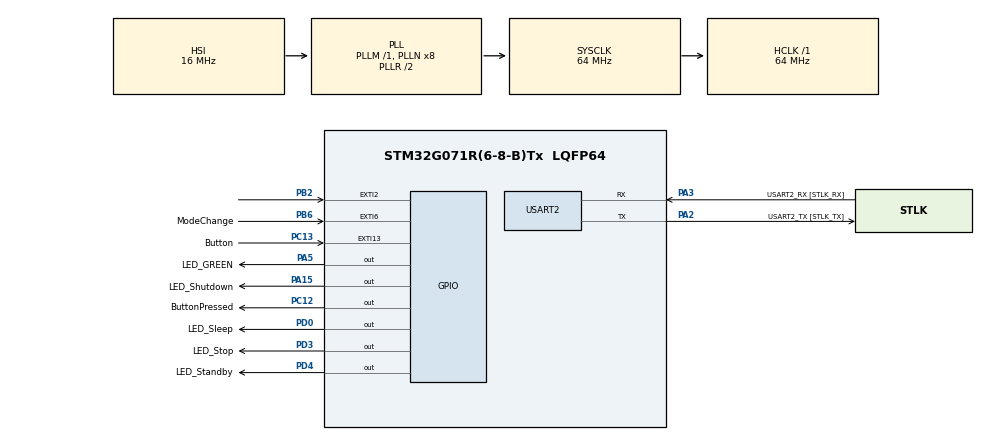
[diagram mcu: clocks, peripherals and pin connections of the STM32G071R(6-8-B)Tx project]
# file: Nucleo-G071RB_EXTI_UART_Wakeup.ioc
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Dma.Request0=USART2_RX
Dma.Request1=USART2_TX
Dma.USART2_RX.0.Direction=DMA_PERIPH_TO_MEMORY
Dma.USART2_RX.0.EventEnable=DISABLE
Dma.USART2_RX.0.Instance=DMA1_Channel1
Dma.USART2_RX.0.MemDataAlignment=DMA_MDATAALIGN_BYTE
Dma.USART2_RX.0.MemInc=DMA_MINC_ENABLE
Dma.USART2_RX.0.Mode=DMA_CIRCULAR
Dma.USART2_RX.0.PeriphDataAlignment=DMA_PDATAALIGN_BYTE
Dma.USART2_RX.0.PeriphInc=DMA_PINC_DISABLE
Dma.USART2_RX.0.Polarity=HAL_DMAMUX_REQ_GEN_RISING
Dma.USART2_RX.0.Priority=DMA_PRIORITY_LOW
Dma.USART2_RX.0.RequestNumber=1
Dma.USART2_RX.0.SignalID=NONE
Dma.USART2_RX.0.SyncEnable=DISABLE
Dma.USART2_RX.0.SyncPolarity=HAL_DMAMUX_SYNC_NO_EVENT
Dma.USART2_RX.0.SyncRequestNumber=1
Dma.USART2_RX.0.SyncSignalID=NONE
Dma.USART2_TX.1.Direction=DMA_MEMORY_TO_PERIPH
Dma.USART2_TX.1.EventEnable=DISABLE
Dma.USART2_TX.1.Instance=DMA1_Channel2
Dma.USART2_TX.1.MemDataAlignment=DMA_MDATAALIGN_BYTE
Dma.USART2_TX.1.MemInc=DMA_MINC_ENABLE
Dma.USART2_TX.1.Mode=DMA_NORMAL
Dma.USART2_TX.1.PeriphDataAlignment=DMA_PDATAALIGN_BYTE
Dma.USART2_TX.1.PeriphInc=DMA_PINC_DISABLE
Dma.USART2_TX.1.Polarity=HAL_DMAMUX_REQ_GEN_RISING
Dma.USART2_TX.1.Priority=DMA_PRIORITY_LOW
Dma.USART2_TX.1.RequestNumber=1
Dma.USART2_TX.1.SignalID=NONE
Dma.USART2_TX.1.SyncEnable=DISABLE
Dma.USART2_TX.1.SyncPolarity=HAL_DMAMUX_SYNC_NO_EVENT
Dma.USART2_TX.1.SyncRequestNumber=1
Dma.USART2_TX.1.SyncSignalID=NONE
Mcu.Family=STM32G0
Mcu.Name=STM32G071R(6-8-B)Tx
Mcu.Package=LQFP64
NVIC.DMA1_Channel1_IRQn=true\:0\:0\:false\:false\:true\:false\:true\:true
NVIC.DMA1_Channel2_3_IRQn=true\:0\:0\:false\:false\:true\:false\:true\:true
NVIC.EXTI2_3_IRQn=true\:0\:0\:false\:false\:true\:true\:true\:true
NVIC.EXTI4_15_IRQn=true\:0\:0\:false\:false\:true\:true\:true\:true
NVIC.USART2_IRQn=true\:0\:0\:false\:false\:true\:true\:true\:true
PA13.GPIO_Label=TMS
PA13.Mode=Serial_Wire
PA13.Signal=SYS_SWDIO
PA14-BOOT0.GPIO_Label=TCK
PA14-BOOT0.Mode=Serial_Wire
PA14-BOOT0.Signal=SYS_SWCLK
PA15.GPIO_Label=LED_Shutdown
PA15.Signal=GPIO_Output
PA2.GPIO_Label=USART2_TX [STLK_TX]
PA2.Mode=Asynchronous
PA2.Signal=USART2_TX
PA3.GPIO_Label=USART2_RX [STLK_RX]
PA3.GPIO_PuPd=GPIO_NOPULL
PA3.Mode=Asynchronous
PA3.Signal=USART2_RX
PA5.GPIO_Label=LED_GREEN
PA5.GPIO_Speed=GPIO_SPEED_FREQ_HIGH
PA5.Signal=GPIO_Output
PB2.GPIO_ModeDefaultEXTI=GPIO_MODE_IT_RISING_FALLING
PB2.GPIO_PuPd=GPIO_PULLUP
PB2.Signal=GPXTI2
PB6.GPIO_Label=ModeChange
PB6.GPIO_ModeDefaultEXTI=GPIO_MODE_IT_RISING_FALLING
PB6.GPIO_PuPd=GPIO_PULLUP
PB6.Signal=GPXTI6
PC12.GPIO_Label=ButtonPressed
PC12.Signal=GPIO_Output
PC13.GPIO_Label=Button
PC13.GPIO_ModeDefaultEXTI=GPIO_MODE_IT_RISING_FALLING
PC13.GPIO_PuPd=GPIO_NOPULL
PC13.Signal=GPXTI13
PD0.GPIO_Label=LED_Sleep
PD0.Signal=GPIO_Output
PD3.GPIO_Label=LED_Stop
PD3.Signal=GPIO_Output
PD4.GPIO_Label=LED_Standby
PD4.Signal=GPIO_Output
ProjectManager.HeapSize=0x200
ProjectManager.StackSize=0x400
ProjectManager.TargetToolchain=STM32CubeIDE
RCC.ADCFreq_Value=64000000
RCC.AHBFreq_Value=64000000
RCC.CortexFreq_Value=64000000
RCC.EXTERNAL_CLOCK_VALUE=12288000
RCC.HCLKFreq_Value=64000000
RCC.HSE_VALUE=8000000
RCC.HSI_VALUE=16000000
RCC.LSE_VALUE=32768
RCC.RCC_MCO1Source=RCC_MCO1SOURCE_HSI
RCC.SYSCLKFreq_VALUE=64000000
RCC.SYSCLKSource=RCC_SYSCLKSOURCE_PLLCLK
RCC.USART2CLockSelection=RCC_USART2CLKSOURCE_HSI
RCC.VCOOutputFreq_Value=128000000
USART2.VirtualMode-Asynchronous=VM_ASYNC
board=NUCLEO-G071RB

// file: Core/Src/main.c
/* USER CODE BEGIN Header */
/**
  ******************************************************************************
  * @file           : main.c
  * @brief          : Main program body
  ******************************************************************************
  * @attention
  *
  * Copyright (c) 2025 STMicroelectronics.
  * All rights reserved.
  *
  * This software is licensed under terms that can be found in the LICENSE file
  * in the root directory of this software component.
  * If no LICENSE file comes with this software, it is provided AS-IS.
  *
  ******************************************************************************
  */
/* USER CODE END Header */
#include "main.h"

UART_HandleTypeDef huart2;
DMA_HandleTypeDef hdma_usart2_rx;
DMA_HandleTypeDef hdma_usart2_tx;

void SystemClock_Config(void);
static void MX_GPIO_Init(void);
static void MX_DMA_Init(void);
static void MX_USART2_UART_Init(void);

int main(void)
{

  /* MCU Configuration--------------------------------------------------------*/

  /* Reset of all peripherals, Initializes the Flash interface and the Systick. */
  HAL_Init();

  /* Configure the system clock */
  SystemClock_Config();

  /* Initialize all configured peripherals */
  MX_GPIO_Init();
  MX_DMA_Init();
  MX_USART2_UART_Init();

  /* Infinite loop */
  /* USER CODE BEGIN WHILE */
  PollingInit();
  while (1)
  {
	  PollingRoutine();
    /* USER CODE END WHILE */

  }
}

void SystemClock_Config(void)
{
  RCC_OscInitTypeDef RCC_OscInitStruct = {0};
  RCC_ClkInitTypeDef RCC_ClkInitStruct = {0};

  /** Configure the main internal regulator output voltage
  */
  HAL_PWREx_ControlVoltageScaling(PWR_REGULATOR_VOLTAGE_SCALE1);

  /** Initializes the RCC Oscillators according to the specified parameters
  * in the RCC_OscInitTypeDef structure.
  */
  RCC_OscInitStruct.OscillatorType = RCC_OSCILLATORTYPE_HSI;
  RCC_OscInitStruct.HSIState = RCC_HSI_ON;
  RCC_OscInitStruct.HSIDiv = RCC_HSI_DIV1;
  RCC_OscInitStruct.HSICalibrationValue = RCC_HSICALIBRATION_DEFAULT;
  RCC_OscInitStruct.PLL.PLLState = RCC_PLL_ON;
  RCC_OscInitStruct.PLL.PLLSource = RCC_PLLSOURCE_HSI;
  RCC_OscInitStruct.PLL.PLLM = RCC_PLLM_DIV1;
  RCC_OscInitStruct.PLL.PLLN = 8;
  RCC_OscInitStruct.PLL.PLLP = RCC_PLLP_DIV2;
  RCC_OscInitStruct.PLL.PLLQ = RCC_PLLQ_DIV2;
  RCC_OscInitStruct.PLL.PLLR = RCC_PLLR_DIV2;
  if (HAL_RCC_OscConfig(&RCC_OscInitStruct) != HAL_OK)
  {
    Error_Handler();
  }

  /** Initializes the CPU, AHB and APB buses clocks
  */
  RCC_ClkInitStruct.ClockType = RCC_CLOCKTYPE_HCLK|RCC_CLOCKTYPE_SYSCLK
                              |RCC_CLOCKTYPE_PCLK1;
  RCC_ClkInitStruct.SYSCLKSource = RCC_SYSCLKSOURCE_PLLCLK;
  RCC_ClkInitStruct.AHBCLKDivider = RCC_SYSCLK_DIV1;
  RCC_ClkInitStruct.APB1CLKDivider = RCC_HCLK_DIV1;

  if (HAL_RCC_ClockConfig(&RCC_ClkInitStruct, FLASH_LATENCY_2) != HAL_OK)
  {
    Error_Handler();
  }
}

static void MX_USART2_UART_Init(void)
{

  huart2.Instance = USART2;
  huart2.Init.BaudRate = 115200;
  huart2.Init.WordLength = UART_WORDLENGTH_8B;
  huart2.Init.StopBits = UART_STOPBITS_1;
  huart2.Init.Parity = UART_PARITY_NONE;
  huart2.Init.Mode = UART_MODE_TX_RX;
  huart2.Init.HwFlowCtl = UART_HWCONTROL_NONE;
  huart2.Init.OverSampling = UART_OVERSAMPLING_16;
  huart2.Init.OneBitSampling = UART_ONE_BIT_SAMPLE_DISABLE;
  huart2.Init.ClockPrescaler = UART_PRESCALER_DIV1;
  huart2.AdvancedInit.AdvFeatureInit = UART_ADVFEATURE_NO_INIT;
  if (HAL_UART_Init(&huart2) != HAL_OK)
  {
    Error_Handler();
  }
  if (HAL_UARTEx_SetTxFifoThreshold(&huart2, UART_TXFIFO_THRESHOLD_1_8) != HAL_OK)
  {
    Error_Handler();
  }
  if (HAL_UARTEx_SetRxFifoThreshold(&huart2, UART_RXFIFO_THRESHOLD_1_8) != HAL_OK)
  {
    Error_Handler();
  }
  if (HAL_UARTEx_DisableFifoMode(&huart2) != HAL_OK)
  {
    Error_Handler();
  }

}

static void MX_DMA_Init(void)
{

  /* DMA controller clock enable */
  __HAL_RCC_DMA1_CLK_ENABLE();

  /* DMA interrupt init */
  /* DMA1_Channel1_IRQn interrupt configuration */
  HAL_NVIC_SetPriority(DMA1_Channel1_IRQn, 0, 0);
  HAL_NVIC_EnableIRQ(DMA1_Channel1_IRQn);
  /* DMA1_Channel2_3_IRQn interrupt configuration */
  HAL_NVIC_SetPriority(DMA1_Channel2_3_IRQn, 0, 0);
  HAL_NVIC_EnableIRQ(DMA1_Channel2_3_IRQn);

}

static void MX_GPIO_Init(void)
{
  GPIO_InitTypeDef GPIO_InitStruct = {0};

  /* GPIO Ports Clock Enable */
  __HAL_RCC_GPIOC_CLK_ENABLE();
  __HAL_RCC_GPIOA_CLK_ENABLE();
  __HAL_RCC_GPIOB_CLK_ENABLE();
  __HAL_RCC_GPIOD_CLK_ENABLE();

  /*Configure GPIO pin Output Level */
  HAL_GPIO_WritePin(ButtonPressed_GPIO_Port, ButtonPressed_Pin, GPIO_PIN_RESET);

  /*Configure GPIO pin Output Level */
  HAL_GPIO_WritePin(GPIOA, LED_GREEN_Pin|LED_Shutdown_Pin, GPIO_PIN_RESET);

  /*Configure GPIO pin Output Level */
  HAL_GPIO_WritePin(GPIOD, LED_Sleep_Pin|LED_Stop_Pin|LED_Standby_Pin, GPIO_PIN_RESET);

  /*Configure GPIO pin : ButtonPressed_Pin */
  GPIO_InitStruct.Pin = ButtonPressed_Pin;
  GPIO_InitStruct.Mode = GPIO_MODE_OUTPUT_PP;
  GPIO_InitStruct.Pull = GPIO_NOPULL;
  GPIO_InitStruct.Speed = GPIO_SPEED_FREQ_LOW;
  HAL_GPIO_Init(ButtonPressed_GPIO_Port, &GPIO_InitStruct);

  /*Configure GPIO pin : Button_Pin */
  GPIO_InitStruct.Pin = Button_Pin;
  GPIO_InitStruct.Mode = GPIO_MODE_IT_RISING_FALLING;
  GPIO_InitStruct.Pull = GPIO_NOPULL;
  HAL_GPIO_Init(Button_GPIO_Port, &GPIO_InitStruct);

  /*Configure GPIO pin : LED_GREEN_Pin */
  GPIO_InitStruct.Pin = LED_GREEN_Pin;
  GPIO_InitStruct.Mode = GPIO_MODE_OUTPUT_PP;
  GPIO_InitStruct.Pull = GPIO_NOPULL;
  GPIO_InitStruct.Speed = GPIO_SPEED_FREQ_HIGH;
  HAL_GPIO_Init(LED_GREEN_GPIO_Port, &GPIO_InitStruct);

  /*Configure GPIO pins : PB2 ModeChange_Pin */
  GPIO_InitStruct.Pin = GPIO_PIN_2|ModeChange_Pin;
  GPIO_InitStruct.Mode = GPIO_MODE_IT_RISING_FALLING;
  GPIO_InitStruct.Pull = GPIO_PULLUP;
  HAL_GPIO_Init(GPIOB, &GPIO_InitStruct);

  /*Configure GPIO pin : LED_Shutdown_Pin */
  GPIO_InitStruct.Pin = LED_Shutdown_Pin;
  GPIO_InitStruct.Mode = GPIO_MODE_OUTPUT_PP;
  GPIO_InitStruct.Pull = GPIO_NOPULL;
  GPIO_InitStruct.Speed = GPIO_SPEED_FREQ_LOW;
  HAL_GPIO_Init(LED_Shutdown_GPIO_Port, &GPIO_InitStruct);

  /*Configure GPIO pins : LED_Sleep_Pin LED_Stop_Pin LED_Standby_Pin */
  GPIO_InitStruct.Pin = LED_Sleep_Pin|LED_Stop_Pin|LED_Standby_Pin;
  GPIO_InitStruct.Mode = GPIO_MODE_OUTPUT_PP;
  GPIO_InitStruct.Pull = GPIO_NOPULL;
  GPIO_InitStruct.Speed = GPIO_SPEED_FREQ_LOW;
  HAL_GPIO_Init(GPIOD, &GPIO_InitStruct);

  /* EXTI interrupt init*/
  HAL_NVIC_SetPriority(EXTI2_3_IRQn, 0, 0);
  HAL_NVIC_EnableIRQ(EXTI2_3_IRQn);

  HAL_NVIC_SetPriority(EXTI4_15_IRQn, 0, 0);
  HAL_NVIC_EnableIRQ(EXTI4_15_IRQn);

}

/* USER CODE BEGIN 4 */
void RunClockConfig(void)
{
	SystemClock_Config();
}
/* USER CODE END 4 */

void Error_Handler(void)
{
  __disable_irq();
  while (1)
  {
  }
}
